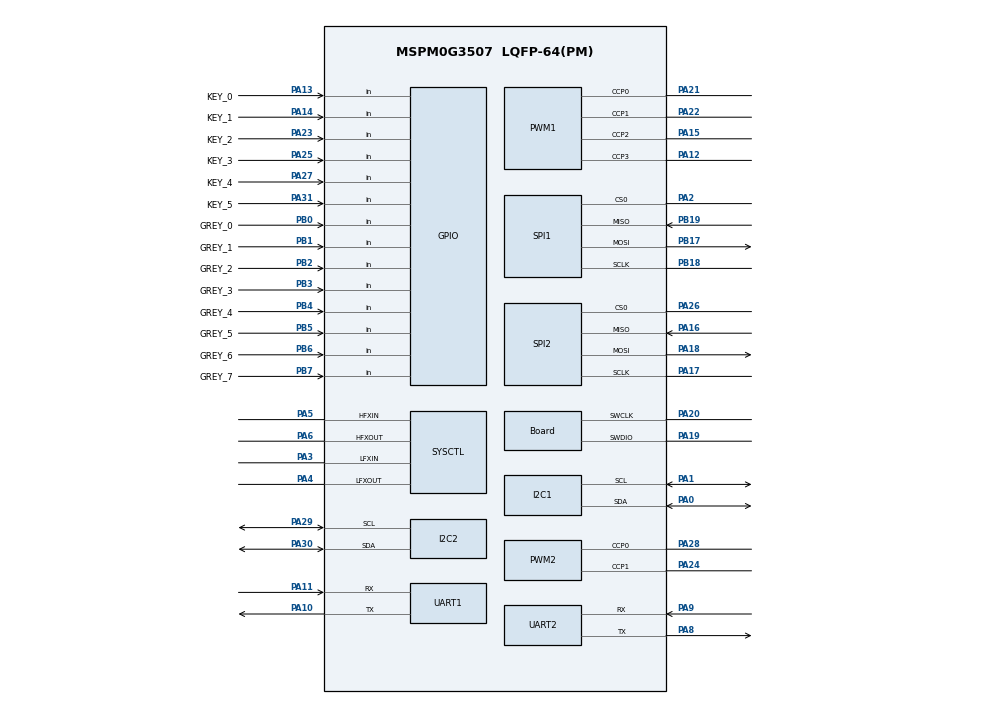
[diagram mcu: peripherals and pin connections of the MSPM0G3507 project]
/**
 * These arguments were used when this file was generated. They will be automatically applied on subsequent loads
 * via the GUI or CLI. Run CLI with '--help' for additional information on how to override these arguments.
 * @cliArgs --device "MSPM0G350X" --part "Default" --package "LQFP-64(PM)" --product "mspm0_sdk@2.05.01.01"
 * @v2CliArgs --device "MSPM0G3507" --package "LQFP-64(PM)" --product "mspm0_sdk@2.05.01.01"
 * @versions {"tool":"1.24.1+4189"}
 */

/**
 * Import the modules used in this configuration.
 */
const Board         = scripting.addModule("/ti/driverlib/Board");
const GPIO          = scripting.addModule("/ti/driverlib/GPIO", {}, false);
const GPIO1         = GPIO.addInstance();
const GPIO2         = GPIO.addInstance();
const GPIO3         = GPIO.addInstance();
const GPIO4         = GPIO.addInstance();
const I2C           = scripting.addModule("/ti/driverlib/I2C", {}, false);
const I2C1          = I2C.addInstance();
const I2C2          = I2C.addInstance();
const PWM           = scripting.addModule("/ti/driverlib/PWM", {}, false);
const PWM1          = PWM.addInstance();
const PWM2          = PWM.addInstance();
const SPI           = scripting.addModule("/ti/driverlib/SPI", {}, false);
const SPI1          = SPI.addInstance();
const SPI2          = SPI.addInstance();
const SYSCTL        = scripting.addModule("/ti/driverlib/SYSCTL");
const TIMER         = scripting.addModule("/ti/driverlib/TIMER", {}, false);
const TIMER1        = TIMER.addInstance();
const UART          = scripting.addModule("/ti/driverlib/UART", {}, false);
const UART1         = UART.addInstance();
const UART2         = UART.addInstance();
const ProjectConfig = scripting.addModule("/ti/project_config/ProjectConfig");

/**
 * Write custom configuration values to the imported modules.
 */
Board.peripheral.$assign          = "DEBUGSS";
Board.peripheral.swclkPin.$assign = "PA20";
Board.peripheral.swdioPin.$assign = "PA19";

GPIO1.$name                         = "GPIO_ENCODER";
GPIO1.port                          = "PORTB";
GPIO1.associatedPins.create(8);
GPIO1.associatedPins[0].direction   = "INPUT";
GPIO1.associatedPins[0].interruptEn = true;
GPIO1.associatedPins[0].polarity    = "RISE";
GPIO1.associatedPins[0].pubChanID   = 1;
GPIO1.associatedPins[0].$name       = "ENCODER_0_A";
GPIO1.associatedPins[1].direction   = "INPUT";
GPIO1.associatedPins[1].$name       = "ENCODER_0_B";
GPIO1.associatedPins[2].direction   = "INPUT";
GPIO1.associatedPins[2].interruptEn = true;
GPIO1.associatedPins[2].polarity    = "RISE";
GPIO1.associatedPins[2].pubChanID   = 1;
GPIO1.associatedPins[2].$name       = "ENCODER_1_A";
GPIO1.associatedPins[3].direction   = "INPUT";
GPIO1.associatedPins[3].$name       = "ENCODER_1_B";
GPIO1.associatedPins[4].direction   = "INPUT";
GPIO1.associatedPins[4].interruptEn = true;
GPIO1.associatedPins[4].polarity    = "RISE";
GPIO1.associatedPins[4].pubChanID   = 1;
GPIO1.associatedPins[4].$name       = "ENCODER_2_A";
GPIO1.associatedPins[5].direction   = "INPUT";
GPIO1.associatedPins[5].$name       = "ENCODER_2_B";
GPIO1.associatedPins[6].direction   = "INPUT";
GPIO1.associatedPins[6].interruptEn = true;
GPIO1.associatedPins[6].polarity    = "RISE";
GPIO1.associatedPins[6].pubChanID   = 1;
GPIO1.associatedPins[6].$name       = "ENCODER_3_A";
GPIO1.associatedPins[7].direction   = "INPUT";
GPIO1.associatedPins[7].$name       = "ENCODER_3_B";

GPIO2.$name                   = "GPIO_MOTOR_DIR";
GPIO2.port                    = "PORTB";
GPIO2.associatedPins.create(4);
GPIO2.associatedPins[0].$name = "MOTOR_0";
GPIO2.associatedPins[1].$name = "MOTOR_1";
GPIO2.associatedPins[2].$name = "MOTOR_2";
GPIO2.associatedPins[3].$name = "MOTOR_3";

GPIO3.$name                              = "GPIO_KEY";
GPIO3.port                               = "PORTA";
GPIO3.associatedPins.create(6);
GPIO3.associatedPins[0].$name            = "KEY_0";
GPIO3.associatedPins[0].direction        = "INPUT";
GPIO3.associatedPins[0].internalResistor = "PULL_UP";
GPIO3.associatedPins[0].pin.$assign      = "PA13";
GPIO3.associatedPins[1].$name            = "KEY_1";
GPIO3.associatedPins[1].direction        = "INPUT";
GPIO3.associatedPins[1].internalResistor = "PULL_UP";
GPIO3.associatedPins[1].pin.$assign      = "PA14";
GPIO3.associatedPins[2].$name            = "KEY_2";
GPIO3.associatedPins[2].direction        = "INPUT";
GPIO3.associatedPins[2].internalResistor = "PULL_UP";
GPIO3.associatedPins[2].pin.$assign      = "PA23";
GPIO3.associatedPins[3].$name            = "KEY_3";
GPIO3.associatedPins[3].direction        = "INPUT";
GPIO3.associatedPins[3].internalResistor = "PULL_UP";
GPIO3.associatedPins[3].pin.$assign      = "PA25";
GPIO3.associatedPins[4].$name            = "KEY_4";
GPIO3.associatedPins[4].direction        = "INPUT";
GPIO3.associatedPins[4].internalResistor = "PULL_UP";
GPIO3.associatedPins[4].pin.$assign      = "PA27";
GPIO3.associatedPins[5].$name            = "KEY_5";
GPIO3.associatedPins[5].direction        = "INPUT";
GPIO3.associatedPins[5].internalResistor = "PULL_UP";
GPIO3.associatedPins[5].pin.$assign      = "PA31";

GPIO4.$name                         = "GPIO_GREY";
GPIO4.port                          = "PORTB";
GPIO4.associatedPins.create(8);
GPIO4.associatedPins[0].$name       = "GREY_0";
GPIO4.associatedPins[0].direction   = "INPUT";
GPIO4.associatedPins[0].pin.$assign = "PB0";
GPIO4.associatedPins[1].$name       = "GREY_1";
GPIO4.associatedPins[1].direction   = "INPUT";
GPIO4.associatedPins[1].pin.$assign = "PB1";
GPIO4.associatedPins[2].direction   = "INPUT";
GPIO4.associatedPins[2].$name       = "GREY_2";
GPIO4.associatedPins[2].pin.$assign = "PB2";
GPIO4.associatedPins[3].$name       = "GREY_3";
GPIO4.associatedPins[3].direction   = "INPUT";
GPIO4.associatedPins[3].pin.$assign = "PB3";
GPIO4.associatedPins[4].$name       = "GREY_4";
GPIO4.associatedPins[4].direction   = "INPUT";
GPIO4.associatedPins[4].pin.$assign = "PB4";
GPIO4.associatedPins[5].$name       = "GREY_5";
GPIO4.associatedPins[5].direction   = "INPUT";
GPIO4.associatedPins[5].pin.$assign = "PB5";
GPIO4.associatedPins[6].$name       = "GREY_6";
GPIO4.associatedPins[6].direction   = "INPUT";
GPIO4.associatedPins[6].pin.$assign = "PB6";
GPIO4.associatedPins[7].$name       = "GREY_7";
GPIO4.associatedPins[7].direction   = "INPUT";
GPIO4.associatedPins[7].pin.$assign = "PB7";

I2C1.$name                             = "OLED";
I2C1.basicEnableController             = true;
I2C1.peripheral.$assign                = "I2C0";
I2C1.peripheral.sdaPin.$assign         = "PA0";
I2C1.peripheral.sclPin.$assign         = "PA1";
I2C1.sdaPinConfig.$name                = "ti_driverlib_gpio_GPIOPinGeneric0";
I2C1.sdaPinConfig.hideOutputInversion  = scripting.forceWrite(false);
I2C1.sdaPinConfig.onlyInternalResistor = scripting.forceWrite(false);
I2C1.sdaPinConfig.passedPeripheralType = scripting.forceWrite("Digital");
I2C1.sclPinConfig.$name                = "ti_driverlib_gpio_GPIOPinGeneric1";
I2C1.sclPinConfig.hideOutputInversion  = scripting.forceWrite(false);
I2C1.sclPinConfig.onlyInternalResistor = scripting.forceWrite(false);
I2C1.sclPinConfig.passedPeripheralType = scripting.forceWrite("Digital");

I2C2.$name                     = "I2C_1";
I2C2.basicEnableController     = true;
I2C2.peripheral.$assign        = "I2C1";
I2C2.peripheral.sdaPin.$assign = "PA30";
I2C2.peripheral.sclPin.$assign = "PA29";
I2C2.sdaPinConfig.$name        = "ti_driverlib_gpio_GPIOPinGeneric2";
I2C2.sclPinConfig.$name        = "ti_driverlib_gpio_GPIOPinGeneric3";

PWM1.$name                              = "MOTOR";
PWM1.ccIndex                            = [0,1,2,3];
PWM1.PWM_CHANNEL_0.$name                = "ti_driverlib_pwm_PWMTimerCC0";
PWM1.PWM_CHANNEL_1.$name                = "ti_driverlib_pwm_PWMTimerCC1";
PWM1.ccp0PinConfig.direction            = scripting.forceWrite("OUTPUT");
PWM1.ccp0PinConfig.hideOutputInversion  = scripting.forceWrite(false);
PWM1.ccp0PinConfig.onlyInternalResistor = scripting.forceWrite(false);
PWM1.ccp0PinConfig.passedPeripheralType = scripting.forceWrite("Digital");
PWM1.ccp0PinConfig.$name                = "ti_driverlib_gpio_GPIOPinGeneric16";
PWM1.ccp1PinConfig.direction            = scripting.forceWrite("OUTPUT");
PWM1.ccp1PinConfig.hideOutputInversion  = scripting.forceWrite(false);
PWM1.ccp1PinConfig.onlyInternalResistor = scripting.forceWrite(false);
PWM1.ccp1PinConfig.passedPeripheralType = scripting.forceWrite("Digital");
PWM1.ccp1PinConfig.$name                = "ti_driverlib_gpio_GPIOPinGeneric17";
PWM1.peripheral.$assign                 = "TIMA0";
PWM1.peripheral.ccp0Pin.$assign         = "PA21";
PWM1.peripheral.ccp1Pin.$assign         = "PA22";
PWM1.peripheral.ccp2Pin.$assign         = "PA15";
PWM1.peripheral.ccp3Pin.$assign         = "PA12";
PWM1.PWM_CHANNEL_2.$name                = "ti_driverlib_pwm_PWMTimerCC2";
PWM1.PWM_CHANNEL_3.$name                = "ti_driverlib_pwm_PWMTimerCC3";
PWM1.ccp2PinConfig.$name                = "ti_driverlib_gpio_GPIOPinGeneric18";
PWM1.ccp3PinConfig.$name                = "ti_driverlib_gpio_GPIOPinGeneric19";

PWM2.$name                              = "SERVO";
PWM2.peripheral.$assign                 = "TIMA1";
PWM2.peripheral.ccp0Pin.$assign         = "PA28";
PWM2.peripheral.ccp1Pin.$assign         = "PA24";
PWM2.PWM_CHANNEL_0.$name                = "ti_driverlib_pwm_PWMTimerCC4";
PWM2.PWM_CHANNEL_1.$name                = "ti_driverlib_pwm_PWMTimerCC5";
PWM2.ccp0PinConfig.direction            = scripting.forceWrite("OUTPUT");
PWM2.ccp0PinConfig.hideOutputInversion  = scripting.forceWrite(false);
PWM2.ccp0PinConfig.onlyInternalResistor = scripting.forceWrite(false);
PWM2.ccp0PinConfig.passedPeripheralType = scripting.forceWrite("Digital");
PWM2.ccp0PinConfig.$name                = "ti_driverlib_gpio_GPIOPinGeneric20";
PWM2.ccp1PinConfig.direction            = scripting.forceWrite("OUTPUT");
PWM2.ccp1PinConfig.hideOutputInversion  = scripting.forceWrite(false);
PWM2.ccp1PinConfig.onlyInternalResistor = scripting.forceWrite(false);
PWM2.ccp1PinConfig.passedPeripheralType = scripting.forceWrite("Digital");
PWM2.ccp1PinConfig.$name                = "ti_driverlib_gpio_GPIOPinGeneric21";

SPI1.$name                      = "SPI_0";
SPI1.peripheral.$assign         = "SPI0";
SPI1.peripheral.sclkPin.$assign = "PB18";
SPI1.peripheral.mosiPin.$assign = "PB17";
SPI1.peripheral.misoPin.$assign = "PB19";
SPI1.peripheral.cs0Pin.$assign  = "PA2";
SPI1.sclkPinConfig.$name        = "ti_driverlib_gpio_GPIOPinGeneric4";
SPI1.mosiPinConfig.$name        = "ti_driverlib_gpio_GPIOPinGeneric5";
SPI1.misoPinConfig.$name        = "ti_driverlib_gpio_GPIOPinGeneric6";
SPI1.cs0PinConfig.$name         = "ti_driverlib_gpio_GPIOPinGeneric7";

SPI2.$name                      = "SPI_1";
SPI2.peripheral.$assign         = "SPI1";
SPI2.peripheral.sclkPin.$assign = "PA17";
SPI2.peripheral.mosiPin.$assign = "PA18";
SPI2.peripheral.misoPin.$assign = "PA16";
SPI2.peripheral.cs0Pin.$assign  = "PA26";
SPI2.sclkPinConfig.$name        = "ti_driverlib_gpio_GPIOPinGeneric8";
SPI2.mosiPinConfig.$name        = "ti_driverlib_gpio_GPIOPinGeneric9";
SPI2.misoPinConfig.$name        = "ti_driverlib_gpio_GPIOPinGeneric10";
SPI2.cs0PinConfig.$name         = "ti_driverlib_gpio_GPIOPinGeneric11";

SYSCTL.MCLKSource                   = "HSCLK";
SYSCTL.HSCLKSource                  = "HFCLK";
SYSCTL.useHFCLK_Manual              = true;
SYSCTL.HFCLKSource                  = "HFXT";
SYSCTL.HFCLK_Freq                   = 40000000;
SYSCTL.forceDefaultClkConfig        = true;
SYSCTL.LFCLKSource                  = "LFXT";
SYSCTL.peripheral.$assign           = "SYSCTL";
SYSCTL.peripheral.lfxInPin.$assign  = "PA3";
SYSCTL.peripheral.lfxOutPin.$assign = "PA4";
SYSCTL.peripheral.hfxInPin.$assign  = "PA5";
SYSCTL.peripheral.hfxOutPin.$assign = "PA6";
scripting.suppress("For best practices when the CPUCLK is running at 32MHz and above, clear the flash status bit using DL_FlashCTL_executeClearStatus\\(\\) before executing any flash operation\\. Otherwise there may be false positives\\.", SYSCTL);

TIMER1.$name              = "TIMER_ENCODER";
TIMER1.peripheral.$assign = "TIMG0";

UART1.$name                            = "K230";
UART1.peripheral.$assign               = "UART0";
UART1.peripheral.rxPin.$assign         = "PA11";
UART1.peripheral.txPin.$assign         = "PA10";
UART1.txPinConfig.direction            = scripting.forceWrite("OUTPUT");
UART1.txPinConfig.hideOutputInversion  = scripting.forceWrite(false);
UART1.txPinConfig.onlyInternalResistor = scripting.forceWrite(false);
UART1.txPinConfig.passedPeripheralType = scripting.forceWrite("Digital");
UART1.txPinConfig.$name                = "ti_driverlib_gpio_GPIOPinGeneric12";
UART1.rxPinConfig.hideOutputInversion  = scripting.forceWrite(false);
UART1.rxPinConfig.onlyInternalResistor = scripting.forceWrite(false);
UART1.rxPinConfig.passedPeripheralType = scripting.forceWrite("Digital");
UART1.rxPinConfig.$name                = "ti_driverlib_gpio_GPIOPinGeneric13";

UART2.$name                    = "UART_1";
UART2.peripheral.$assign       = "UART1";
UART2.peripheral.rxPin.$assign = "PA9";
UART2.peripheral.txPin.$assign = "PA8";
UART2.txPinConfig.$name        = "ti_driverlib_gpio_GPIOPinGeneric14";
UART2.rxPinConfig.$name        = "ti_driverlib_gpio_GPIOPinGeneric15";

ProjectConfig.compiler = "ticlang";

/**
 * Pinmux solution for unlocked pins/peripherals. This ensures that minor changes to the automatic solver in a future
 * version of the tool will not impact the pinmux you originally saw.  These lines can be completely deleted in order to
 * re-solve from scratch.
 */
GPIO1.associatedPins[0].pin.$suggestSolution = "PB27";
GPIO1.associatedPins[1].pin.$suggestSolution = "PB26";
GPIO1.associatedPins[2].pin.$suggestSolution = "PB25";
GPIO1.associatedPins[3].pin.$suggestSolution = "PB24";
GPIO1.associatedPins[4].pin.$suggestSolution = "PB23";
GPIO1.associatedPins[5].pin.$suggestSolution = "PB22";
GPIO1.associatedPins[6].pin.$suggestSolution = "PB21";
GPIO1.associatedPins[7].pin.$suggestSolution = "PB20";
GPIO2.associatedPins[0].pin.$suggestSolution = "PB16";
GPIO2.associatedPins[1].pin.$suggestSolution = "PB15";
GPIO2.associatedPins[2].pin.$suggestSolution = "PB14";
GPIO2.associatedPins[3].pin.$suggestSolution = "PB13";
